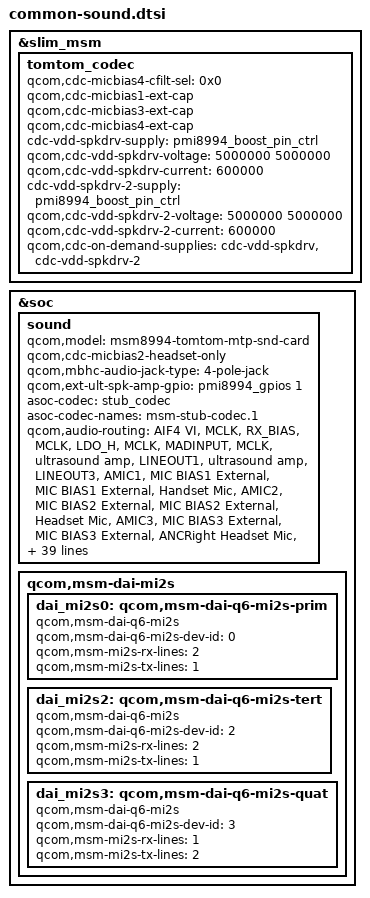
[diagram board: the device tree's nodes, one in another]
/* Copyright (c) 2017, The Linux Foundation. All rights reserved.
 *
 * This program is free software; you can redistribute it and/or modify
 * it under the terms of the GNU General Public License version 2 and
 * only version 2 as published by the Free Software Foundation.
 *
 * This program is distributed in the hope that it will be useful,
 * but WITHOUT ANY WARRANTY; without even the implied warranty of
 * MERCHANTABILITY or FITNESS FOR A PARTICULAR PURPOSE.  See the
 * GNU General Public License for more details.
 */

&slim_msm {
	tomtom_codec {
		qcom,cdc-micbias4-cfilt-sel = <0x0>;
		qcom,cdc-micbias1-ext-cap;
		qcom,cdc-micbias3-ext-cap;
		qcom,cdc-micbias4-ext-cap;
		cdc-vdd-spkdrv-supply = <&pmi8994_boost_pin_ctrl>;
		qcom,cdc-vdd-spkdrv-voltage = <5000000 5000000>;
		qcom,cdc-vdd-spkdrv-current = <600000>;

		cdc-vdd-spkdrv-2-supply = <&pmi8994_boost_pin_ctrl>;
		qcom,cdc-vdd-spkdrv-2-voltage = <5000000 5000000>;
		qcom,cdc-vdd-spkdrv-2-current = <600000>;

		qcom,cdc-on-demand-supplies = "cdc-vdd-spkdrv",
					      "cdc-vdd-spkdrv-2";
	};	
};

&soc {
	sound {
		qcom,model = "msm8994-tomtom-mtp-snd-card";

		qcom,cdc-micbias2-headset-only;
		qcom,mbhc-audio-jack-type = "4-pole-jack";
		qcom,ext-ult-spk-amp-gpio = <&pmi8994_gpios 1 0>;
		asoc-codec = <&stub_codec>;
		asoc-codec-names = "msm-stub-codec.1";

		qcom,audio-routing =
			"AIF4 VI", "MCLK",
			"RX_BIAS", "MCLK",
			"LDO_H", "MCLK",
			"MADINPUT", "MCLK",
			"ultrasound amp", "LINEOUT1",
			"ultrasound amp", "LINEOUT3",
			"AMIC1", "MIC BIAS1 External",
			"MIC BIAS1 External", "Handset Mic",
			"AMIC2", "MIC BIAS2 External",
			"MIC BIAS2 External", "Headset Mic",
			"AMIC3", "MIC BIAS3 External",
			"MIC BIAS3 External", "ANCRight Headset Mic",
			"AMIC4", "MIC BIAS1 External",
			"MIC BIAS1 External", "ANCLeft Headset Mic",
			"AMIC5", "MIC BIAS3 External",
			"MIC BIAS3 External", "Analog Mic5",
			"AMIC6", "MIC BIAS4 External",
			"MIC BIAS4 External", "Analog Mic6",
			"DMIC1", "MIC BIAS1 External",
			"MIC BIAS1 External", "Digital Mic1",
			"DMIC2", "MIC BIAS1 External",
			"MIC BIAS1 External", "Digital Mic2",
			"DMIC3", "MIC BIAS3 External",
			"MIC BIAS3 External", "Digital Mic3",
			"DMIC4", "MIC BIAS3 External",
			"MIC BIAS3 External", "Digital Mic4",
			"DMIC5", "MIC BIAS4 External",
			"MIC BIAS4 External", "Digital Mic5",
			"DMIC6", "MIC BIAS4 External",
			"MIC BIAS4 External", "Digital Mic6";

		asoc-cpu = <&dai_pri_auxpcm>, <&dai_sec_auxpcm>, <&dai_hdmi>, <&dai_mi2s0>,
				<&dai_mi2s2>, <&dai_mi2s3>,
				<&sb_0_rx>, <&sb_0_tx>, <&sb_1_rx>, <&sb_1_tx>,
				<&sb_2_rx>, <&sb_2_tx>, <&sb_3_rx>, <&sb_3_tx>,
				<&sb_4_rx>, <&sb_4_tx>, <&sb_5_tx>, <&bt_sco_rx>,
				<&bt_sco_tx>, <&int_fm_rx>, <&int_fm_tx>, <&afe_pcm_rx>,
				<&afe_pcm_tx>, <&afe_proxy_rx>, <&afe_proxy_tx>,
				<&incall_record_rx>, <&incall_record_tx>, <&incall_music_rx>,
				<&incall_music2_rx>;

		asoc-cpu-names = "msm-dai-q6-auxpcm.1", "msm-dai-q6-auxpcm.2",
				"msm-dai-q6-hdmi.8", "msm-dai-q6-mi2s.0",
				"msm-dai-q6-mi2s.2", "msm-dai-q6-mi2s.3",
				"msm-dai-q6-dev.16384", "msm-dai-q6-dev.16385",
				"msm-dai-q6-dev.16386", "msm-dai-q6-dev.16387",
				"msm-dai-q6-dev.16388", "msm-dai-q6-dev.16389",
				"msm-dai-q6-dev.16390", "msm-dai-q6-dev.16391",
				"msm-dai-q6-dev.16392", "msm-dai-q6-dev.16393",
				"msm-dai-q6-dev.16395", "msm-dai-q6-dev.12288",
				"msm-dai-q6-dev.12289", "msm-dai-q6-dev.12292",
				"msm-dai-q6-dev.12293", "msm-dai-q6-dev.224",
				"msm-dai-q6-dev.225", "msm-dai-q6-dev.241",
				"msm-dai-q6-dev.240", "msm-dai-q6-dev.32771",
				"msm-dai-q6-dev.32772", "msm-dai-q6-dev.32773",
				"msm-dai-q6-dev.32770";
	};

	qcom,msm-dai-mi2s {
		/delete-node/ qcom,msm-dai-q6-mi2s-prim;
		dai_mi2s0: qcom,msm-dai-q6-mi2s-prim {
			compatible = "qcom,msm-dai-q6-mi2s";
			qcom,msm-dai-q6-mi2s-dev-id = <0>;
			qcom,msm-mi2s-rx-lines = <2>;
			qcom,msm-mi2s-tx-lines = <1>;
		};
		dai_mi2s2: qcom,msm-dai-q6-mi2s-tert {
			compatible = "qcom,msm-dai-q6-mi2s";
			qcom,msm-dai-q6-mi2s-dev-id = <2>;
			qcom,msm-mi2s-rx-lines = <2>;
			qcom,msm-mi2s-tx-lines = <1>;
		};
		dai_mi2s3: qcom,msm-dai-q6-mi2s-quat {
			compatible = "qcom,msm-dai-q6-mi2s";
			qcom,msm-dai-q6-mi2s-dev-id = <3>;
			qcom,msm-mi2s-rx-lines = <1>;
			qcom,msm-mi2s-tx-lines = <2>;
		};
	};
};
